# f28e12x_cpu_sys_regs register map
Vendor: Texas Instruments
Peripheral module from a debugger description file (folder C2000).
Address unit: 16 bits
Registers are 32-bit, read-write, no defined reset value unless marked. A register's access mark holds for its fields unless they carry their own. Offsets are as the file gives them; lines under a group give offsets from that group; [hi:lo] are bit positions; {n}, {i} and the like mark numbered series; 'fields as' and 'values as' point back to an identical list; <NAME> marks a mode.

## CPU_SYS_REGS — CPU SYS Registers
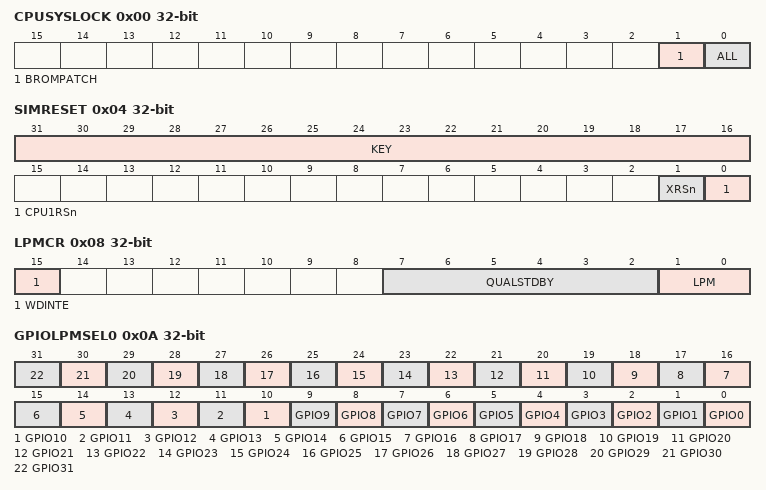
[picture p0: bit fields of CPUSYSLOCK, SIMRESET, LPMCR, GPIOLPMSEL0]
0x00 CPUSYSLOCK — Lock bit for CPUSYS registers
  [1] BROMPATCH — Lock bit for BROMPATCH registers
  [0] ALL — Lock bit for CPUSYS registers
0x02 PIEVERRADDR — PIE Vector Fetch Error Address register
  [21:0] ADDR — PIE Vector Fetch Error Handler Routine Address
0x04 SIMRESET — Simulated Reset Register
  [31:16] KEY — Key value to enable write
  [1] XRSn — Generates a simulated XRSn
  [0] CPU1RSn — Generates a reset to CPU
0x08 LPMCR — LPM Control Register
  [15] WDINTE — Enable for WDINT wakeup from STANDBY
  [7:2] QUALSTDBY — STANDBY Wakeup Pin Qualification Setting
  [1:0] LPM — Low Power Mode setting
0x0A GPIOLPMSEL0 — GPIO LPM Wakeup select registers
  [n] GPIO{n} (n=0..31) — GPIO{n} Enable for LPM Wakeup
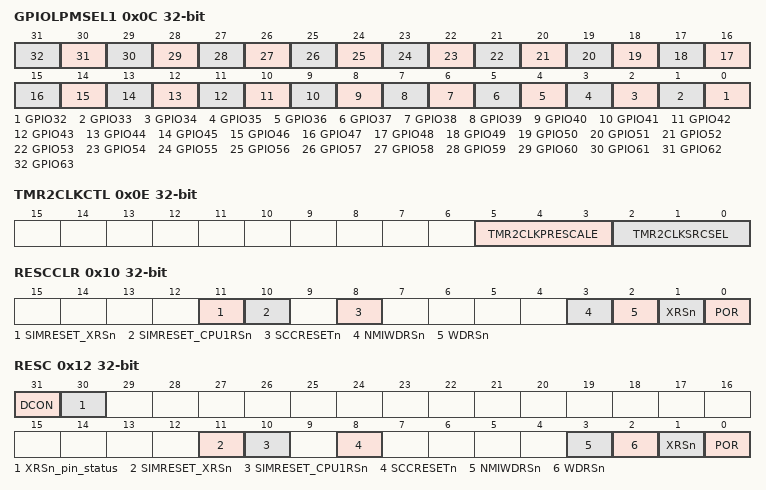
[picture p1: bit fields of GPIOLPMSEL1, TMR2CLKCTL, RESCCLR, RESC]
0x0C GPIOLPMSEL1 — GPIO LPM Wakeup select registers
  [n-32] GPIO{n} (n=32..63) — GPIO{n} Enable for LPM Wakeup
0x0E TMR2CLKCTL — Timer2 Clock Measurement functionality control register
  [5:3] TMR2CLKPRESCALE — CPU Timer 2 Clock Pre-Scale Value
  [2:0] TMR2CLKSRCSEL — CPU Timer 2 Clock Source Select Bit
0x10 RESCCLR — Reset Cause Clear Register
  [11] SIMRESET_XRSn — SIMRESET_XRSn Reset Cause Indication Bit
  [10] SIMRESET_CPU1RSn — SIMRESET_CPU1RSn Reset Cause Indication Bit
  [8] SCCRESETn — SCCRESETn Reset Cause Indication Bit
  [3] NMIWDRSn — NMIWDRSn Reset Cause Indication Bit
  [2] WDRSn — WDRSn Reset Cause Indication Bit
  [1] XRSn — XRSn Reset Cause Indication Bit
  [0] POR — POR Reset Cause Indication Bit
0x12 RESC ro — Reset Cause register
  [31] DCON — Debugger conntion status to C28x
  [30] XRSn_pin_status
  [11] SIMRESET_XRSn — SIMRESET_XRSn Reset Cause Indication Bit
  [10] SIMRESET_CPU1RSn — SIMRESET_CPU1RSn Reset Cause Indication Bit
  [8] SCCRESETn — SCCRESETn Reset Cause Indication Bit
  [3] NMIWDRSn — NMIWDRSn Reset Cause Indication Bit
  [2] WDRSn — WDRSn Reset Cause Indication Bit
  [1] XRSn — XRSn Reset Cause Indication Bit
  [0] POR — POR Reset Cause Indication Bit
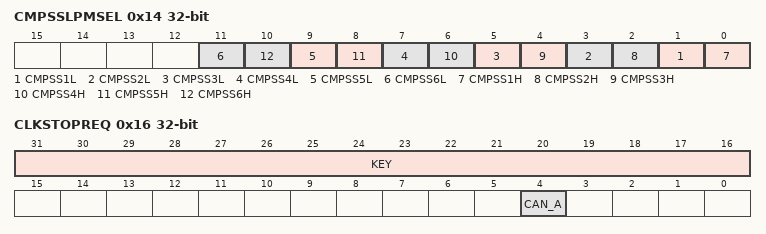
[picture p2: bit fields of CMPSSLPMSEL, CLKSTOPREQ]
0x14 CMPSSLPMSEL — CMPSS LPM Wakeup select registers
  [2n-1] CMPSS{n}L (n=1..6) — CMPSS{n}L Enable for LPM Wakeup
  [2n-2] CMPSS{n}H (n=1..6) — CMPSS{n}H Enable for LPM Wakeup
0x16 CLKSTOPREQ — Peripheral Clock Stop Request Register
  [31:16] KEY — Key for register write
  [4] CAN_A — CAN_A Clock Stop Request Bit
0x18 CLKSTOPACK ro — Peripheral Clock Stop Ackonwledge Register
  [4] CAN_A — CAN_A Clock Stop Ack Bit
0x1A USER_REG1_SYSRSn — Software Configurable registers reset by SYSRSn
  [31:0] BITS — SW configurable bits
0x1C USER_REG2_SYSRSn — Software Configurable registers reset by SYSRSn
  [31:0] BITS — SW configurable bits
0x1E USER_REG1_XRSn — Software Configurable registers reset by XRSn
  [31:0] BITS — SW configurable bits
0x20 USER_REG2_XRSn — Software Configurable registers reset by XRSn
  [31:0] BITS — SW configurable bits
{0x20+2i} USER_REG{i}_PORESETn (i=1..4) — Software Configurable registers reset by PORESETn
  [31:0] BITS — SW configurable bits
0x3C PERCLKCR — Peripheral Clock Control
  [0] TBCLKSYNC — PWM Time Base Clock sync
